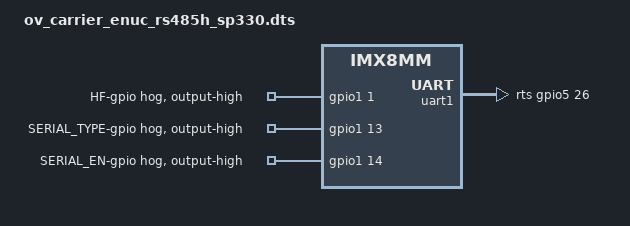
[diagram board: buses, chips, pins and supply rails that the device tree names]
/**
 * Portenta-M8 dtb overlay file
 * Arduino 2021
 * Enable RS485 half duplex on Arduino eNUC carrier board
 * where SP330 ic is used.
 * Gpios:
 * DE controls tx
 * REn controls rx
 * behaviour is always rx except while transmitting
 */

/dts-v1/;
/plugin/;

#include "imx8mm-pinfunc.h"

/ {
	compatible = "fsl,imx8mm-evk", "fsl,imx8mm";

	fragment@0 {
		target = <&iomuxc>;
		__overlay__ {
			imx8mm {
				pinctrl_uart1: uart1grp {
					fsl,pins = <
						MX8MM_IOMUXC_UART1_RXD_UART1_DCE_RX     0x140
						MX8MM_IOMUXC_UART1_TXD_UART1_DCE_TX     0x140
					>;
				};
			};
		};
	};

	fragment@1 {
		target = <&uart1>;
		__overlay__ {
			pinctrl-names = "default";
			pinctrl-0 = <&pinctrl_uart1>;
			linux,rs485-enabled-at-boot-time;
			//rs485-rx-during-tx;
			rs485-rts-delay = <1 1>;  // In milliseconds
			status = "okay";
			cts-gpios = <&gpio5 27 GPIO_ACTIVE_LOW>; // RTS -> REn
			rts-gpios = <&gpio5 26 GPIO_ACTIVE_HIGH>; // CTS -> DE
			status = "okay";
			};
	};

	fragment@2 {
		target = <&gpio1>;
		__overlay__ {
			HF {
				gpio-hog;
				gpios = <1 0>;
				output-high;
				line-name = "HF-gpio";
			};
			SERIAL_TYPE {
				gpio-hog;
				gpios = <13 0>;
				output-high;
				line-name = "SERIAL_TYPE-gpio";
			};
			SERIAL_EN {
				gpio-hog;
				gpios = <14 0>;
				output-high;
				line-name = "SERIAL_EN-gpio";
			};
		};
	};
};
